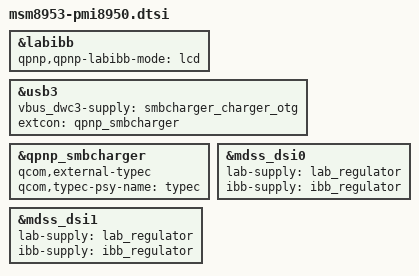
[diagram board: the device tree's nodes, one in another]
&labibb {
	status = "ok";
	qpnp,qpnp-labibb-mode = "lcd";
};

&usb3 {
	vbus_dwc3-supply = <&smbcharger_charger_otg>;
	extcon = <&qpnp_smbcharger>;
};

&qpnp_smbcharger {
	qcom,external-typec;
	qcom,typec-psy-name = "typec";
};

&mdss_dsi0 {
	lab-supply = <&lab_regulator>;
	ibb-supply = <&ibb_regulator>;
};

&mdss_dsi1 {
	lab-supply = <&lab_regulator>;
	ibb-supply = <&ibb_regulator>;
};
